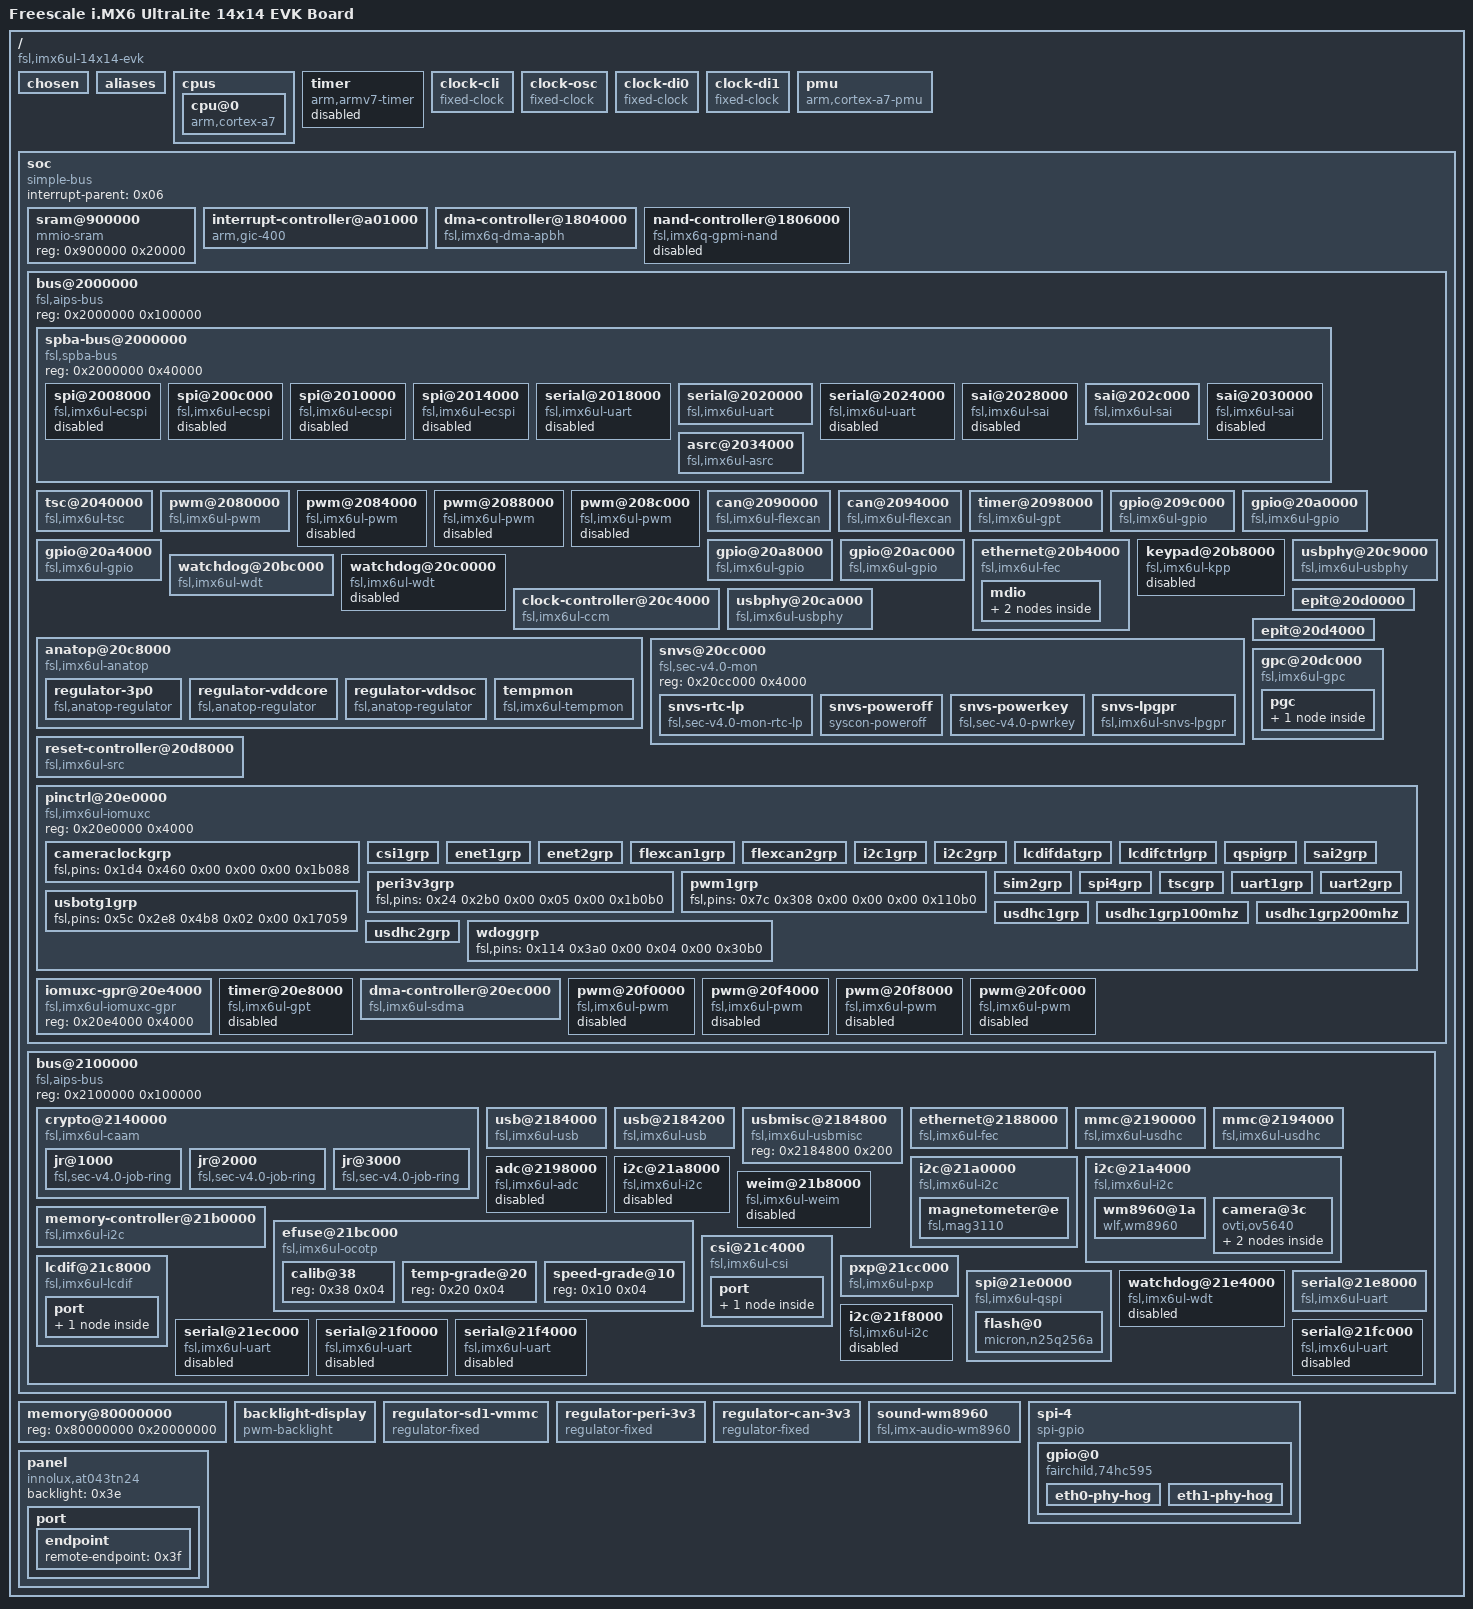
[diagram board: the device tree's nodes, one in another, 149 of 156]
/dts-v1/;

/ {
	#address-cells = <0x01>;
	#size-cells = <0x01>;
	model = "Freescale i.MX6 UltraLite 14x14 EVK Board";
	compatible = "fsl,imx6ul-14x14-evk\0fsl,imx6ul";

	chosen {
		stdout-path = "/soc/bus@2000000/spba-bus@2000000/serial@2020000";
	};

	aliases {
		ethernet0 = "/soc/bus@2100000/ethernet@2188000";
		ethernet1 = "/soc/bus@2000000/ethernet@20b4000";
		gpio0 = "/soc/bus@2000000/gpio@209c000";
		gpio1 = "/soc/bus@2000000/gpio@20a0000";
		gpio2 = "/soc/bus@2000000/gpio@20a4000";
		gpio3 = "/soc/bus@2000000/gpio@20a8000";
		gpio4 = "/soc/bus@2000000/gpio@20ac000";
		i2c0 = "/soc/bus@2100000/i2c@21a0000";
		i2c1 = "/soc/bus@2100000/i2c@21a4000";
		i2c2 = "/soc/bus@2100000/i2c@21a8000";
		i2c3 = "/soc/bus@2100000/i2c@21f8000";
		mmc0 = "/soc/bus@2100000/mmc@2190000";
		mmc1 = "/soc/bus@2100000/mmc@2194000";
		serial0 = "/soc/bus@2000000/spba-bus@2000000/serial@2020000";
		serial1 = "/soc/bus@2100000/serial@21e8000";
		serial2 = "/soc/bus@2100000/serial@21ec000";
		serial3 = "/soc/bus@2100000/serial@21f0000";
		serial4 = "/soc/bus@2100000/serial@21f4000";
		serial5 = "/soc/bus@2100000/serial@21fc000";
		serial6 = "/soc/bus@2000000/spba-bus@2000000/serial@2018000";
		serial7 = "/soc/bus@2000000/spba-bus@2000000/serial@2024000";
		sai1 = "/soc/bus@2000000/spba-bus@2000000/sai@2028000";
		sai2 = "/soc/bus@2000000/spba-bus@2000000/sai@202c000";
		sai3 = "/soc/bus@2000000/spba-bus@2000000/sai@2030000";
		spi0 = "/soc/bus@2000000/spba-bus@2000000/spi@2008000";
		spi1 = "/soc/bus@2000000/spba-bus@2000000/spi@200c000";
		spi2 = "/soc/bus@2000000/spba-bus@2000000/spi@2010000";
		spi3 = "/soc/bus@2000000/spba-bus@2000000/spi@2014000";
		usb0 = "/soc/bus@2100000/usb@2184000";
		usb1 = "/soc/bus@2100000/usb@2184200";
		usbphy0 = "/soc/bus@2000000/usbphy@20c9000";
		usbphy1 = "/soc/bus@2000000/usbphy@20ca000";
	};

	cpus {
		#address-cells = <0x01>;
		#size-cells = <0x00>;

		cpu@0 {
			compatible = "arm,cortex-a7";
			device_type = "cpu";
			reg = <0x00>;
			clock-frequency = <0x297c1e00>;
			clock-latency = <0xee6c>;
			#cooling-cells = <0x02>;
			operating-points = <0xa9ec0 0x137478 0x80e80 0x11edd8 0x60ae0 0xfa3e8 0x30570 0xe7ef0>;
			fsl,soc-operating-points = <0xa9ec0 0x137478 0x80e80 0x11edd8 0x60ae0 0x11edd8 0x30570 0x11edd8>;
			clocks = <0x01 0x5d 0x01 0x1a 0x01 0x26 0x01 0xdb 0x01 0x38 0x01 0x39 0x01 0x19>;
			clock-names = "arm\0pll2_bus\0pll2_pfd2_396m\0secondary_sel\0step\0pll1_sw\0pll1_sys";
			arm-supply = <0x02>;
			soc-supply = <0x03>;
			nvmem-cells = <0x04>;
			nvmem-cell-names = "speed_grade";
		};
	};

	timer {
		compatible = "arm,armv7-timer";
		interrupts = <0x01 0x0d 0x108 0x01 0x0e 0x108 0x01 0x0b 0x108 0x01 0x0a 0x108>;
		interrupt-parent = <0x05>;
		status = "disabled";
	};

	clock-cli {
		compatible = "fixed-clock";
		#clock-cells = <0x00>;
		clock-frequency = <0x8000>;
		clock-output-names = "ckil";
		phandle = <0x17>;
	};

	clock-osc {
		compatible = "fixed-clock";
		#clock-cells = <0x00>;
		clock-frequency = <0x16e3600>;
		clock-output-names = "osc";
		phandle = <0x18>;
	};

	clock-di0 {
		compatible = "fixed-clock";
		#clock-cells = <0x00>;
		clock-frequency = <0x00>;
		clock-output-names = "ipp_di0";
		phandle = <0x19>;
	};

	clock-di1 {
		compatible = "fixed-clock";
		#clock-cells = <0x00>;
		clock-frequency = <0x00>;
		clock-output-names = "ipp_di1";
		phandle = <0x1a>;
	};

	pmu {
		compatible = "arm,cortex-a7-pmu";
		interrupt-parent = <0x06>;
		interrupts = <0x00 0x5e 0x04>;
	};

	soc {
		#address-cells = <0x01>;
		#size-cells = <0x01>;
		compatible = "simple-bus";
		interrupt-parent = <0x06>;
		ranges;

		sram@900000 {
			compatible = "mmio-sram";
			reg = <0x900000 0x20000>;
			ranges = <0x00 0x900000 0x20000>;
			#address-cells = <0x01>;
			#size-cells = <0x01>;
		};

		interrupt-controller@a01000 {
			compatible = "arm,gic-400\0arm,cortex-a7-gic";
			interrupts = <0x01 0x09 0x104>;
			#interrupt-cells = <0x03>;
			interrupt-controller;
			interrupt-parent = <0x05>;
			reg = <0xa01000 0x1000 0xa02000 0x2000 0xa04000 0x2000 0xa06000 0x2000>;
			phandle = <0x05>;
		};

		dma-controller@1804000 {
			compatible = "fsl,imx6q-dma-apbh\0fsl,imx28-dma-apbh";
			reg = <0x1804000 0x2000>;
			interrupts = <0x00 0x0d 0x04 0x00 0x0d 0x04 0x00 0x0d 0x04 0x00 0x0d 0x04>;
			#dma-cells = <0x01>;
			dma-channels = <0x04>;
			clocks = <0x01 0x80>;
			phandle = <0x07>;
		};

		nand-controller@1806000 {
			compatible = "fsl,imx6q-gpmi-nand";
			#address-cells = <0x01>;
			#size-cells = <0x00>;
			reg = <0x1806000 0x2000 0x1808000 0x2000>;
			reg-names = "gpmi-nand\0bch";
			interrupts = <0x00 0x0f 0x04>;
			interrupt-names = "bch";
			clocks = <0x01 0x85 0x01 0x86 0x01 0x84 0x01 0x83 0x01 0xdc>;
			clock-names = "gpmi_io\0gpmi_apb\0gpmi_bch\0gpmi_bch_apb\0per1_bch";
			dmas = <0x07 0x00>;
			dma-names = "rx-tx";
			status = "disabled";
		};

		bus@2000000 {
			compatible = "fsl,aips-bus\0simple-bus";
			#address-cells = <0x01>;
			#size-cells = <0x01>;
			reg = <0x2000000 0x100000>;
			ranges;

			spba-bus@2000000 {
				compatible = "fsl,spba-bus\0simple-bus";
				#address-cells = <0x01>;
				#size-cells = <0x01>;
				reg = <0x2000000 0x40000>;
				ranges;

				spi@2008000 {
					#address-cells = <0x01>;
					#size-cells = <0x00>;
					compatible = "fsl,imx6ul-ecspi\0fsl,imx51-ecspi";
					reg = <0x2008000 0x4000>;
					interrupts = <0x00 0x1f 0x04>;
					clocks = <0x01 0x8b 0x01 0x8b>;
					clock-names = "ipg\0per";
					dmas = <0x08 0x03 0x07 0x01 0x08 0x04 0x07 0x02>;
					dma-names = "rx\0tx";
					status = "disabled";
				};

				spi@200c000 {
					#address-cells = <0x01>;
					#size-cells = <0x00>;
					compatible = "fsl,imx6ul-ecspi\0fsl,imx51-ecspi";
					reg = <0x200c000 0x4000>;
					interrupts = <0x00 0x20 0x04>;
					clocks = <0x01 0x8c 0x01 0x8c>;
					clock-names = "ipg\0per";
					dmas = <0x08 0x05 0x07 0x01 0x08 0x06 0x07 0x02>;
					dma-names = "rx\0tx";
					status = "disabled";
				};

				spi@2010000 {
					#address-cells = <0x01>;
					#size-cells = <0x00>;
					compatible = "fsl,imx6ul-ecspi\0fsl,imx51-ecspi";
					reg = <0x2010000 0x4000>;
					interrupts = <0x00 0x21 0x04>;
					clocks = <0x01 0x8d 0x01 0x8d>;
					clock-names = "ipg\0per";
					dmas = <0x08 0x07 0x07 0x01 0x08 0x08 0x07 0x02>;
					dma-names = "rx\0tx";
					status = "disabled";
				};

				spi@2014000 {
					#address-cells = <0x01>;
					#size-cells = <0x00>;
					compatible = "fsl,imx6ul-ecspi\0fsl,imx51-ecspi";
					reg = <0x2014000 0x4000>;
					interrupts = <0x00 0x22 0x04>;
					clocks = <0x01 0x8e 0x01 0x8e>;
					clock-names = "ipg\0per";
					dmas = <0x08 0x09 0x07 0x01 0x08 0x0a 0x07 0x02>;
					dma-names = "rx\0tx";
					status = "disabled";
				};

				serial@2018000 {
					compatible = "fsl,imx6ul-uart\0fsl,imx6q-uart";
					reg = <0x2018000 0x4000>;
					interrupts = <0x00 0x27 0x04>;
					clocks = <0x01 0xc9 0x01 0xca>;
					clock-names = "ipg\0per";
					status = "disabled";
				};

				serial@2020000 {
					compatible = "fsl,imx6ul-uart\0fsl,imx6q-uart";
					reg = <0x2020000 0x4000>;
					interrupts = <0x00 0x1a 0x04>;
					clocks = <0x01 0xbd 0x01 0xbe>;
					clock-names = "ipg\0per";
					status = "okay";
					pinctrl-names = "default";
					pinctrl-0 = <0x09>;
				};

				serial@2024000 {
					compatible = "fsl,imx6ul-uart\0fsl,imx6q-uart";
					reg = <0x2024000 0x4000>;
					interrupts = <0x00 0x28 0x04>;
					clocks = <0x01 0xcb 0x01 0xcc>;
					clock-names = "ipg\0per";
					status = "disabled";
				};

				sai@2028000 {
					#sound-dai-cells = <0x00>;
					compatible = "fsl,imx6ul-sai\0fsl,imx6sx-sai";
					reg = <0x2028000 0x4000>;
					interrupts = <0x00 0x61 0x04>;
					clocks = <0x01 0xb3 0x01 0xb2 0x01 0x00 0x01 0x00>;
					clock-names = "bus\0mclk1\0mclk2\0mclk3";
					dmas = <0x08 0x23 0x18 0x00 0x08 0x24 0x18 0x00>;
					dma-names = "rx\0tx";
					status = "disabled";
				};

				sai@202c000 {
					#sound-dai-cells = <0x00>;
					compatible = "fsl,imx6ul-sai\0fsl,imx6sx-sai";
					reg = <0x202c000 0x4000>;
					interrupts = <0x00 0x62 0x04>;
					clocks = <0x01 0xb5 0x01 0xb4 0x01 0x00 0x01 0x00>;
					clock-names = "bus\0mclk1\0mclk2\0mclk3";
					dmas = <0x08 0x25 0x18 0x00 0x08 0x26 0x18 0x00>;
					dma-names = "rx\0tx";
					status = "okay";
					pinctrl-names = "default";
					pinctrl-0 = <0x0a>;
					assigned-clocks = <0x01 0x47 0x01 0xb4>;
					assigned-clock-parents = <0x01 0x32>;
					assigned-clock-rates = <0x00 0xbb8000>;
					fsl,sai-mclk-direction-output;
					phandle = <0x3a>;
				};

				sai@2030000 {
					#sound-dai-cells = <0x00>;
					compatible = "fsl,imx6ul-sai\0fsl,imx6sx-sai";
					reg = <0x2030000 0x4000>;
					interrupts = <0x00 0x18 0x04>;
					clocks = <0x01 0xb7 0x01 0xb6 0x01 0x00 0x01 0x00>;
					clock-names = "bus\0mclk1\0mclk2\0mclk3";
					dmas = <0x08 0x27 0x18 0x00 0x08 0x28 0x18 0x00>;
					dma-names = "rx\0tx";
					status = "disabled";
				};

				asrc@2034000 {
					compatible = "fsl,imx6ul-asrc\0fsl,imx53-asrc";
					reg = <0x2034000 0x4000>;
					interrupts = <0x00 0x32 0x04>;
					clocks = <0x01 0x81 0x01 0x82 0x01 0x00 0x01 0x00 0x01 0x00 0x01 0x00 0x01 0x00 0x01 0x00 0x01 0x00 0x01 0x00 0x01 0x00 0x01 0x00 0x01 0x00 0x01 0x00 0x01 0x00 0x01 0xbc 0x01 0x00 0x01 0x00 0x01 0xbb>;
					clock-names = "mem\0ipg\0asrck_0\0asrck_1\0asrck_2\0asrck_3\0asrck_4\0asrck_5\0asrck_6\0asrck_7\0asrck_8\0asrck_9\0asrck_a\0asrck_b\0asrck_c\0asrck_d\0asrck_e\0asrck_f\0spba";
					dmas = <0x08 0x11 0x17 0x01 0x08 0x12 0x17 0x01 0x08 0x13 0x17 0x01 0x08 0x14 0x17 0x01 0x08 0x15 0x17 0x01 0x08 0x16 0x17 0x01>;
					dma-names = "rxa\0rxb\0rxc\0txa\0txb\0txc";
					fsl,asrc-rate = <0xbb80>;
					fsl,asrc-width = <0x10>;
					status = "okay";
					phandle = <0x3c>;
				};
			};

			tsc@2040000 {
				compatible = "fsl,imx6ul-tsc";
				reg = <0x2040000 0x4000 0x219c000 0x4000>;
				interrupts = <0x00 0x03 0x04 0x00 0x65 0x04>;
				clocks = <0x01 0x64 0x01 0x7c>;
				clock-names = "tsc\0adc";
				status = "okay";
				pinctrl-names = "default";
				pinctrl-0 = <0x0b>;
				xnur-gpio = <0x0c 0x03 0x01>;
				measure-delay-time = <0xffff>;
				pre-charge-time = <0xfff>;
			};

			pwm@2080000 {
				compatible = "fsl,imx6ul-pwm\0fsl,imx27-pwm";
				reg = <0x2080000 0x4000>;
				interrupts = <0x00 0x53 0x04>;
				clocks = <0x01 0xa7 0x01 0xa7>;
				clock-names = "ipg\0per";
				#pwm-cells = <0x02>;
				status = "okay";
				pinctrl-names = "default";
				pinctrl-0 = <0x0d>;
				phandle = <0x37>;
			};

			pwm@2084000 {
				compatible = "fsl,imx6ul-pwm\0fsl,imx27-pwm";
				reg = <0x2084000 0x4000>;
				interrupts = <0x00 0x54 0x04>;
				clocks = <0x01 0xa8 0x01 0xa8>;
				clock-names = "ipg\0per";
				#pwm-cells = <0x03>;
				status = "disabled";
			};

			pwm@2088000 {
				compatible = "fsl,imx6ul-pwm\0fsl,imx27-pwm";
				reg = <0x2088000 0x4000>;
				interrupts = <0x00 0x55 0x04>;
				clocks = <0x01 0xa9 0x01 0xa9>;
				clock-names = "ipg\0per";
				#pwm-cells = <0x03>;
				status = "disabled";
			};

			pwm@208c000 {
				compatible = "fsl,imx6ul-pwm\0fsl,imx27-pwm";
				reg = <0x208c000 0x4000>;
				interrupts = <0x00 0x56 0x04>;
				clocks = <0x01 0xaa 0x01 0xaa>;
				clock-names = "ipg\0per";
				#pwm-cells = <0x03>;
				status = "disabled";
			};

			can@2090000 {
				compatible = "fsl,imx6ul-flexcan\0fsl,imx6q-flexcan";
				reg = <0x2090000 0x4000>;
				interrupts = <0x00 0x6e 0x04>;
				clocks = <0x01 0x94 0x01 0x95>;
				clock-names = "ipg\0per";
				fsl,stop-mode = <0x0e 0x10 0x01>;
				status = "okay";
				pinctrl-names = "default";
				pinctrl-0 = <0x0f>;
				xceiver-supply = <0x10>;
			};

			can@2094000 {
				compatible = "fsl,imx6ul-flexcan\0fsl,imx6q-flexcan";
				reg = <0x2094000 0x4000>;
				interrupts = <0x00 0x6f 0x04>;
				clocks = <0x01 0x96 0x01 0x97>;
				clock-names = "ipg\0per";
				fsl,stop-mode = <0x0e 0x10 0x02>;
				status = "okay";
				pinctrl-names = "default";
				pinctrl-0 = <0x11>;
				xceiver-supply = <0x10>;
			};

			timer@2098000 {
				compatible = "fsl,imx6ul-gpt\0fsl,imx6sx-gpt";
				reg = <0x2098000 0x4000>;
				interrupts = <0x00 0x37 0x04>;
				clocks = <0x01 0x98 0x01 0x99>;
				clock-names = "ipg\0per";
			};

			gpio@209c000 {
				compatible = "fsl,imx6ul-gpio\0fsl,imx35-gpio";
				reg = <0x209c000 0x4000>;
				interrupts = <0x00 0x42 0x04 0x00 0x43 0x04>;
				clocks = <0x01 0xf4>;
				gpio-controller;
				#gpio-cells = <0x02>;
				interrupt-controller;
				#interrupt-cells = <0x02>;
				gpio-ranges = <0x12 0x00 0x17 0x0a 0x12 0x0a 0x11 0x06 0x12 0x10 0x21 0x10>;
				phandle = <0x0c>;
			};

			gpio@20a0000 {
				compatible = "fsl,imx6ul-gpio\0fsl,imx35-gpio";
				reg = <0x20a0000 0x4000>;
				interrupts = <0x00 0x44 0x04 0x00 0x45 0x04>;
				clocks = <0x01 0xf5>;
				gpio-controller;
				#gpio-cells = <0x02>;
				interrupt-controller;
				#interrupt-cells = <0x02>;
				gpio-ranges = <0x12 0x00 0x31 0x10 0x12 0x10 0x6f 0x06>;
			};

			gpio@20a4000 {
				compatible = "fsl,imx6ul-gpio\0fsl,imx35-gpio";
				reg = <0x20a4000 0x4000>;
				interrupts = <0x00 0x46 0x04 0x00 0x47 0x04>;
				clocks = <0x01 0xf6>;
				gpio-controller;
				#gpio-cells = <0x02>;
				interrupt-controller;
				#interrupt-cells = <0x02>;
				gpio-ranges = <0x12 0x00 0x41 0x1d>;
			};

			gpio@20a8000 {
				compatible = "fsl,imx6ul-gpio\0fsl,imx35-gpio";
				reg = <0x20a8000 0x4000>;
				interrupts = <0x00 0x48 0x04 0x00 0x49 0x04>;
				clocks = <0x01 0xf7>;
				gpio-controller;
				#gpio-cells = <0x02>;
				interrupt-controller;
				#interrupt-cells = <0x02>;
				gpio-ranges = <0x12 0x00 0x5e 0x11 0x12 0x11 0x75 0x0c>;
			};

			gpio@20ac000 {
				compatible = "fsl,imx6ul-gpio\0fsl,imx35-gpio";
				reg = <0x20ac000 0x4000>;
				interrupts = <0x00 0x4a 0x04 0x00 0x4b 0x04>;
				clocks = <0x01 0xf8>;
				gpio-controller;
				#gpio-cells = <0x02>;
				interrupt-controller;
				#interrupt-cells = <0x02>;
				gpio-ranges = <0x12 0x00 0x07 0x0a 0x12 0x0a 0x05 0x02>;
				phandle = <0x39>;
			};

			ethernet@20b4000 {
				compatible = "fsl,imx6ul-fec\0fsl,imx6q-fec";
				reg = <0x20b4000 0x4000>;
				interrupt-names = "int0\0pps";
				interrupts = <0x00 0x78 0x04 0x00 0x79 0x04>;
				clocks = <0x01 0x90 0x01 0x91 0x01 0x30 0x01 0xfd>;
				clock-names = "ipg\0ahb\0ptp\0enet_clk_ref";
				fsl,num-tx-queues = <0x01>;
				fsl,num-rx-queues = <0x01>;
				fsl,stop-mode = <0x0e 0x10 0x04>;
				fsl,magic-packet;
				status = "okay";
				pinctrl-names = "default";
				pinctrl-0 = <0x13>;
				phy-mode = "rmii";
				phy-handle = <0x14>;
				phy-supply = <0x15>;

				mdio {
					#address-cells = <0x01>;
					#size-cells = <0x00>;

					ethernet-phy@2 {
						compatible = "ethernet-phy-id0022.1560";
						reg = <0x02>;
						micrel,led-mode = <0x01>;
						clocks = <0x01 0x2c>;
						clock-names = "rmii-ref";
						phandle = <0x25>;
					};

					ethernet-phy@1 {
						compatible = "ethernet-phy-id0022.1560";
						reg = <0x01>;
						micrel,led-mode = <0x01>;
						clocks = <0x01 0x2d>;
						clock-names = "rmii-ref";
						phandle = <0x14>;
					};
				};
			};

			keypad@20b8000 {
				compatible = "fsl,imx6ul-kpp\0fsl,imx21-kpp";
				reg = <0x20b8000 0x4000>;
				interrupts = <0x00 0x52 0x04>;
				clocks = <0x01 0xe0>;
				status = "disabled";
			};

			watchdog@20bc000 {
				compatible = "fsl,imx6ul-wdt\0fsl,imx21-wdt";
				reg = <0x20bc000 0x4000>;
				interrupts = <0x00 0x50 0x04>;
				clocks = <0x01 0xd0>;
				pinctrl-names = "default";
				pinctrl-0 = <0x16>;
				fsl,ext-reset-output;
			};

			watchdog@20c0000 {
				compatible = "fsl,imx6ul-wdt\0fsl,imx21-wdt";
				reg = <0x20c0000 0x4000>;
				interrupts = <0x00 0x51 0x04>;
				clocks = <0x01 0xd1>;
				status = "disabled";
			};

			clock-controller@20c4000 {
				compatible = "fsl,imx6ul-ccm";
				reg = <0x20c4000 0x4000>;
				interrupts = <0x00 0x57 0x04 0x00 0x58 0x04>;
				#clock-cells = <0x01>;
				clocks = <0x17 0x18 0x19 0x1a>;
				clock-names = "ckil\0osc\0ipp_di0\0ipp_di1";
				assigned-clocks = <0x01 0x32>;
				assigned-clock-rates = <0x2ee00000>;
				phandle = <0x01>;
			};

			anatop@20c8000 {
				compatible = "fsl,imx6ul-anatop\0fsl,imx6q-anatop\0syscon\0simple-mfd";
				reg = <0x20c8000 0x1000>;
				interrupts = <0x00 0x31 0x04 0x00 0x36 0x04 0x00 0x7f 0x04>;
				phandle = <0x1b>;

				regulator-3p0 {
					compatible = "fsl,anatop-regulator";
					regulator-name = "vdd3p0";
					regulator-min-microvolt = <0x280de8>;
					regulator-max-microvolt = <0x33e140>;
					anatop-reg-offset = <0x120>;
					anatop-vol-bit-shift = <0x08>;
					anatop-vol-bit-width = <0x05>;
					anatop-min-bit-val = <0x00>;
					anatop-min-voltage = <0x280de8>;
					anatop-max-voltage = <0x33e140>;
					anatop-enable-bit = <0x00>;
					phandle = <0x1e>;
				};

				regulator-vddcore {
					compatible = "fsl,anatop-regulator";
					regulator-name = "cpu";
					regulator-min-microvolt = <0xb1008>;
					regulator-max-microvolt = <0x162010>;
					regulator-always-on;
					anatop-reg-offset = <0x140>;
					anatop-vol-bit-shift = <0x00>;
					anatop-vol-bit-width = <0x05>;
					anatop-delay-reg-offset = <0x170>;
					anatop-delay-bit-shift = <0x18>;
					anatop-delay-bit-width = <0x02>;
					anatop-min-bit-val = <0x01>;
					anatop-min-voltage = <0xb1008>;
					anatop-max-voltage = <0x162010>;
					phandle = <0x02>;
				};

				regulator-vddsoc {
					compatible = "fsl,anatop-regulator";
					regulator-name = "vddsoc";
					regulator-min-microvolt = <0xb1008>;
					regulator-max-microvolt = <0x162010>;
					regulator-always-on;
					anatop-reg-offset = <0x140>;
					anatop-vol-bit-shift = <0x12>;
					anatop-vol-bit-width = <0x05>;
					anatop-delay-reg-offset = <0x170>;
					anatop-delay-bit-shift = <0x1c>;
					anatop-delay-bit-width = <0x02>;
					anatop-min-bit-val = <0x01>;
					anatop-min-voltage = <0xb1008>;
					anatop-max-voltage = <0x162010>;
					phandle = <0x03>;
				};

				tempmon {
					compatible = "fsl,imx6ul-tempmon\0fsl,imx6sx-tempmon";
					interrupt-parent = <0x06>;
					interrupts = <0x00 0x31 0x04>;
					fsl,tempmon = <0x1b>;
					nvmem-cells = <0x1c 0x1d>;
					nvmem-cell-names = "calib\0temp_grade";
					clocks = <0x01 0x1b>;
				};
			};

			usbphy@20c9000 {
				compatible = "fsl,imx6ul-usbphy\0fsl,imx23-usbphy";
				reg = <0x20c9000 0x1000>;
				interrupts = <0x00 0x2c 0x04>;
				clocks = <0x01 0x20>;
				phy-3p0-supply = <0x1e>;
				fsl,anatop = <0x1b>;
				fsl,tx-d-cal = <0x6a>;
				phandle = <0x20>;
			};

			usbphy@20ca000 {
				compatible = "fsl,imx6ul-usbphy\0fsl,imx23-usbphy";
				reg = <0x20ca000 0x1000>;
				interrupts = <0x00 0x2d 0x04>;
				clocks = <0x01 0x21>;
				phy-3p0-supply = <0x1e>;
				fsl,anatop = <0x1b>;
				fsl,tx-d-cal = <0x6a>;
				phandle = <0x23>;
			};

			snvs@20cc000 {
				compatible = "fsl,sec-v4.0-mon\0syscon\0simple-mfd";
				reg = <0x20cc000 0x4000>;
				phandle = <0x1f>;

				snvs-rtc-lp {
					compatible = "fsl,sec-v4.0-mon-rtc-lp";
					regmap = <0x1f>;
					offset = <0x34>;
					interrupts = <0x00 0x13 0x04 0x00 0x14 0x04>;
				};

				snvs-poweroff {
					compatible = "syscon-poweroff";
					regmap = <0x1f>;
					offset = <0x38>;
					value = <0x60>;
					mask = <0x60>;
					status = "okay";
				};

				snvs-powerkey {
					compatible = "fsl,sec-v4.0-pwrkey";
					regmap = <0x1f>;
					interrupts = <0x00 0x04 0x04>;
					linux,keycode = <0x74>;
					wakeup-source;
					status = "okay";
				};

				snvs-lpgpr {
					compatible = "fsl,imx6ul-snvs-lpgpr";
				};
			};

			epit@20d0000 {
				reg = <0x20d0000 0x4000>;
				interrupts = <0x00 0x38 0x04>;
			};

			epit@20d4000 {
				reg = <0x20d4000 0x4000>;
				interrupts = <0x00 0x39 0x04>;
			};

			reset-controller@20d8000 {
				compatible = "fsl,imx6ul-src\0fsl,imx51-src";
				reg = <0x20d8000 0x4000>;
				interrupts = <0x00 0x5b 0x04 0x00 0x60 0x04>;
				#reset-cells = <0x01>;
			};

			gpc@20dc000 {
				compatible = "fsl,imx6ul-gpc\0fsl,imx6q-gpc";
				reg = <0x20dc000 0x4000>;
				interrupt-controller;
				#interrupt-cells = <0x03>;
				interrupts = <0x00 0x59 0x04>;
				interrupt-parent = <0x05>;
				clocks = <0x01 0x64>;
				clock-names = "ipg";
				phandle = <0x06>;

				pgc {
					#address-cells = <0x01>;
					#size-cells = <0x00>;

					power-domain@0 {
						reg = <0x00>;
						#power-domain-cells = <0x00>;
					};
				};
			};

			pinctrl@20e0000 {
				compatible = "fsl,imx6ul-iomuxc";
				reg = <0x20e0000 0x4000>;
				pinctrl-names = "default";
				phandle = <0x12>;

				cameraclockgrp {
					fsl,pins = <0x1d4 0x460 0x00 0x00 0x00 0x1b088>;
					phandle = <0x2d>;
				};

				csi1grp {
					fsl,pins = <0x1d8 0x464 0x528 0x00 0x01 0x1b088 0x1dc 0x468 0x52c 0x00 0x00 0x1b088 0x1e0 0x46c 0x524 0x00 0x00 0x1b088 0x1e4 0x470 0x4c4 0x00 0x00 0x1b088 0x1e8 0x474 0x4c8 0x00 0x00 0x1b088 0x1ec 0x478 0x4d8 0x00 0x01 0x1b088 0x1f0 0x47c 0x4cc 0x00 0x00 0x1b088 0x1f4 0x480 0x4dc 0x00 0x01 0x1b088 0x1f8 0x484 0x4e0 0x00 0x01 0x1b088 0x1fc 0x488 0x4e4 0x00 0x01 0x1b088 0x200 0x48c 0x4e8 0x00 0x01 0x1b088>;
					phandle = <0x30>;
				};

				enet1grp {
					fsl,pins = <0xcc 0x358 0x00 0x00 0x00 0x1b0b0 0xe0 0x36c 0x00 0x00 0x00 0x1b0b0 0xc4 0x350 0x00 0x00 0x00 0x1b0b0 0xc8 0x354 0x00 0x00 0x00 0x1b0b0 0xd8 0x364 0x00 0x00 0x00 0x1b0b0 0xd0 0x35c 0x00 0x00 0x00 0x1b0b0 0xd4 0x360 0x00 0x00 0x00 0x1b0b0 0xdc 0x368 0x574 0x04 0x02 0x4001b031>;
					phandle = <0x24>;
				};

				enet2grp {
					fsl,pins = <0x78 0x304 0x00 0x01 0x00 0x1b0b0 0x74 0x300 0x580 0x01 0x00 0x1b0b0 0xec 0x378 0x00 0x00 0x00 0x1b0b0 0x100 0x38c 0x00 0x00 0x00 0x1b0b0 0xe4 0x370 0x00 0x00 0x00 0x1b0b0 0xe8 0x374 0x00 0x00 0x00 0x1b0b0 0xf8 0x384 0x00 0x00 0x00 0x1b0b0 0xf0 0x37c 0x00 0x00 0x00 0x1b0b0 0xf4 0x380 0x00 0x00 0x00 0x1b0b0 0xfc 0x388 0x57c 0x04 0x02 0x4001b031>;
					phandle = <0x13>;
				};

				flexcan1grp {
					fsl,pins = <0xb0 0x33c 0x584 0x02 0x00 0x1b020 0xac 0x338 0x00 0x02 0x00 0x1b020>;
					phandle = <0x0f>;
				};

				flexcan2grp {
					fsl,pins = <0xa0 0x32c 0x588 0x02 0x00 0x1b020 0x9c 0x328 0x00 0x02 0x00 0x1b020>;
					phandle = <0x11>;
				};

				i2c1grp {
					fsl,pins = <0xb4 0x340 0x5a4 0x02 0x01 0x4001b8b0 0xb8 0x344 0x5a8 0x02 0x02 0x4001b8b0>;
					phandle = <0x2b>;
				};

				i2c2grp {
					fsl,pins = <0xbc 0x348 0x5ac 0x02 0x02 0x4001b8b0 0xc0 0x34c 0x5b0 0x02 0x02 0x4001b8b0>;
					phandle = <0x2c>;
				};

				lcdifdatgrp {
					fsl,pins = <0x118 0x3a4 0x00 0x00 0x00 0x79 0x11c 0x3a8 0x00 0x00 0x00 0x79 0x120 0x3ac 0x00 0x00 0x00 0x79 0x124 0x3b0 0x00 0x00 0x00 0x79 0x128 0x3b4 0x00 0x00 0x00 0x79 0x12c 0x3b8 0x00 0x00 0x00 0x79 0x130 0x3bc 0x00 0x00 0x00 0x79 0x134 0x3c0 0x00 0x00 0x00 0x79 0x138 0x3c4 0x00 0x00 0x00 0x79 0x13c 0x3c8 0x00 0x00 0x00 0x79 0x140 0x3cc 0x00 0x00 0x00 0x79 0x144 0x3d0 0x00 0x00 0x00 0x79 0x148 0x3d4 0x00 0x00 0x00 0x79 0x14c 0x3d8 0x00 0x00 0x00 0x79 0x150 0x3dc 0x00 0x00 0x00 0x79 0x154 0x3e0 0x00 0x00 0x00 0x79 0x158 0x3e4 0x00 0x00 0x00 0x79 0x15c 0x3e8 0x00 0x00 0x00 0x79 0x160 0x3ec 0x00 0x00 0x00 0x79 0x164 0x3f0 0x00 0x00 0x00 0x79 0x168 0x3f4 0x00 0x00 0x00 0x79 0x16c 0x3f8 0x00 0x00 0x00 0x79 0x170 0x3fc 0x00 0x00 0x00 0x79 0x174 0x400 0x00 0x00 0x00 0x79>;
					phandle = <0x32>;
				};

				lcdifctrlgrp {
					fsl,pins = <0x104 0x390 0x00 0x00 0x00 0x79 0x108 0x394 0x00 0x00 0x00 0x79 0x10c 0x398 0x5dc 0x00 0x00 0x79 0x110 0x39c 0x00 0x00 0x00 0x79 0x40 0x2cc 0x00 0x05 0x00 0x79>;
					phandle = <0x33>;
				};

				qspigrp {
					fsl,pins = <0x1a4 0x430 0x00 0x02 0x00 0x70a1 0x1a8 0x434 0x00 0x02 0x00 0x70a1 0x1ac 0x438 0x00 0x02 0x00 0x70a1 0x1b0 0x43c 0x00 0x02 0x00 0x70a1 0x1b4 0x440 0x00 0x02 0x00 0x70a1 0x1b8 0x444 0x00 0x02 0x00 0x70a1>;
					phandle = <0x35>;
				};

				sai2grp {
					fsl,pins = <0x50 0x2dc 0x5f8 0x02 0x00 0x17088 0x4c 0x2d8 0x5fc 0x02 0x00 0x17088 0x58 0x2e4 0x00 0x02 0x00 0x11088 0x54 0x2e0 0x5f4 0x02 0x00 0x11088 0x48 0x2d4 0x5f0 0x02 0x00 0x17088 0x2c 0x2b8 0x00 0x05 0x00 0x17059>;
					phandle = <0x0a>;
				};

				peri3v3grp {
					fsl,pins = <0x24 0x2b0 0x00 0x05 0x00 0x1b0b0>;
					phandle = <0x38>;
				};

				pwm1grp {
					fsl,pins = <0x7c 0x308 0x00 0x00 0x00 0x110b0>;
					phandle = <0x0d>;
				};

				sim2grp {
					fsl,pins = <0x1f0 0x47c 0x00 0x02 0x00 0xb808 0x1f4 0x480 0x00 0x02 0x00 0x31 0x1f8 0x484 0x00 0x02 0x00 0xb808 0x1fc 0x488 0x00 0x02 0x00 0xb808 0x200 0x48c 0x00 0x02 0x00 0xb809 0x1ec 0x478 0x00 0x05 0x00 0x3008>;
				};

				spi4grp {
					fsl,pins = <0x14 0x2a0 0x00 0x05 0x00 0x70a1 0x18 0x2a4 0x00 0x05 0x00 0x70a1 0x38 0x2c4 0x00 0x05 0x00 0x70a1 0x3c 0x2c8 0x00 0x05 0x00 0x80000000>;
					phandle = <0x3d>;
				};

				tscgrp {
					fsl,pins = <0x60 0x2ec 0x00 0x05 0x00 0xb0 0x64 0x2f0 0x00 0x05 0x00 0xb0 0x68 0x2f4 0x00 0x05 0x00 0xb0 0x6c 0x2f8 0x00 0x05 0x00 0xb0>;
					phandle = <0x0b>;
				};

				uart1grp {
					fsl,pins = <0x84 0x310 0x00 0x00 0x00 0x1b0b1 0x88 0x314 0x624 0x00 0x03 0x1b0b1>;
					phandle = <0x09>;
				};

				uart2grp {
					fsl,pins = <0x94 0x320 0x00 0x00 0x00 0x1b0b1 0x98 0x324 0x62c 0x00 0x01 0x1b0b1 0xa8 0x334 0x628 0x04 0x03 0x1b0b1 0xa4 0x330 0x00 0x04 0x00 0x1b0b1>;
					phandle = <0x36>;
				};

				usbotg1grp {
					fsl,pins = <0x5c 0x2e8 0x4b8 0x02 0x00 0x17059>;
					phandle = <0x22>;
				};

				usdhc1grp {
					fsl,pins = <0x1bc 0x448 0x00 0x00 0x00 0x17059 0x1c0 0x44c 0x00 0x00 0x00 0x10059 0x1c4 0x450 0x00 0x00 0x00 0x17059 0x1c8 0x454 0x00 0x00 0x00 0x17059 0x1cc 0x458 0x00 0x00 0x00 0x17059 0x1d0 0x45c 0x00 0x00 0x00 0x17059 0x90 0x31c 0x00 0x05 0x00 0x17059 0x70 0x2fc 0x00 0x04 0x00 0x17059 0x80 0x30c 0x00 0x05 0x00 0x17059>;
					phandle = <0x26>;
				};

				usdhc1grp100mhz {
					fsl,pins = <0x1bc 0x448 0x00 0x00 0x00 0x170b9 0x1c0 0x44c 0x00 0x00 0x00 0x100b9 0x1c4 0x450 0x00 0x00 0x00 0x170b9 0x1c8 0x454 0x00 0x00 0x00 0x170b9 0x1cc 0x458 0x00 0x00 0x00 0x170b9 0x1d0 0x45c 0x00 0x00 0x00 0x170b9>;
					phandle = <0x27>;
				};

				usdhc1grp200mhz {
					fsl,pins = <0x1bc 0x448 0x00 0x00 0x00 0x170f9 0x1c0 0x44c 0x00 0x00 0x00 0x100f9 0x1c4 0x450 0x00 0x00 0x00 0x170f9 0x1c8 0x454 0x00 0x00 0x00 0x170f9 0x1cc 0x458 0x00 0x00 0x00 0x170f9 0x1d0 0x45c 0x00 0x00 0x00 0x170f9>;
					phandle = <0x28>;
				};

				usdhc2grp {
					fsl,pins = <0x178 0x404 0x670 0x01 0x02 0x17059 0x17c 0x408 0x678 0x01 0x02 0x17059 0x180 0x40c 0x67c 0x01 0x02 0x17059 0x184 0x410 0x680 0x01 0x02 0x17059 0x188 0x414 0x684 0x01 0x01 0x17059 0x18c 0x418 0x688 0x01 0x02 0x17059>;
					phandle = <0x2a>;
				};

				wdoggrp {
					fsl,pins = <0x114 0x3a0 0x00 0x04 0x00 0x30b0>;
					phandle = <0x16>;
				};
			};

			iomuxc-gpr@20e4000 {
				compatible = "fsl,imx6ul-iomuxc-gpr\0fsl,imx6q-iomuxc-gpr\0syscon";
				reg = <0x20e4000 0x4000>;
				phandle = <0x0e>;
			};

			timer@20e8000 {
				compatible = "fsl,imx6ul-gpt\0fsl,imx6sx-gpt";
				reg = <0x20e8000 0x4000>;
				interrupts = <0x00 0x6d 0x04>;
				clocks = <0x01 0x9a 0x01 0x9b>;
				clock-names = "ipg\0per";
				status = "disabled";
			};

			dma-controller@20ec000 {
				compatible = "fsl,imx6ul-sdma\0fsl,imx6q-sdma\0fsl,imx35-sdma";
				reg = <0x20ec000 0x4000>;
				interrupts = <0x00 0x02 0x04>;
				clocks = <0x01 0x64 0x01 0xb8>;
				clock-names = "ipg\0ahb";
				#dma-cells = <0x03>;
				fsl,sdma-ram-script-name = "imx/sdma/sdma-imx6q.bin";
				phandle = <0x08>;
			};

			pwm@20f0000 {
				compatible = "fsl,imx6ul-pwm\0fsl,imx27-pwm";
				reg = <0x20f0000 0x4000>;
				interrupts = <0x00 0x72 0x04>;
				clocks = <0x01 0xab 0x01 0xab>;
				clock-names = "ipg\0per";
				#pwm-cells = <0x03>;
				status = "disabled";
			};

			pwm@20f4000 {
				compatible = "fsl,imx6ul-pwm\0fsl,imx27-pwm";
				reg = <0x20f4000 0x4000>;
				interrupts = <0x00 0x73 0x04>;
				clocks = <0x01 0xac 0x01 0xac>;
				clock-names = "ipg\0per";
				#pwm-cells = <0x03>;
				status = "disabled";
			};

			pwm@20f8000 {
				compatible = "fsl,imx6ul-pwm\0fsl,imx27-pwm";
				reg = <0x20f8000 0x4000>;
				interrupts = <0x00 0x74 0x04>;
				clocks = <0x01 0xad 0x01 0xad>;
				clock-names = "ipg\0per";
				#pwm-cells = <0x03>;
				status = "disabled";
			};

			pwm@20fc000 {
				compatible = "fsl,imx6ul-pwm\0fsl,imx27-pwm";
				reg = <0x20fc000 0x4000>;
				interrupts = <0x00 0x75 0x04>;
				clocks = <0x01 0xae 0x01 0xae>;
				clock-names = "ipg\0per";
				#pwm-cells = <0x03>;
				status = "disabled";
			};
		};

		bus@2100000 {
			compatible = "fsl,aips-bus\0simple-bus";
			#address-cells = <0x01>;
			#size-cells = <0x01>;
			reg = <0x2100000 0x100000>;
			ranges;

			crypto@2140000 {
				compatible = "fsl,imx6ul-caam\0fsl,sec-v4.0";
				#address-cells = <0x01>;
				#size-cells = <0x01>;
				reg = <0x2140000 0x3c000>;
				ranges = <0x00 0x2140000 0x3c000>;
				interrupts = <0x00 0x30 0x04>;
				clocks = <0x01 0x89 0x01 0x88 0x01 0x87>;
				clock-names = "ipg\0aclk\0mem";

				jr@1000 {
					compatible = "fsl,sec-v4.0-job-ring";
					reg = <0x1000 0x1000>;
					interrupts = <0x00 0x69 0x04>;
				};

				jr@2000 {
					compatible = "fsl,sec-v4.0-job-ring";
					reg = <0x2000 0x1000>;
					interrupts = <0x00 0x6a 0x04>;
				};

				jr@3000 {
					compatible = "fsl,sec-v4.0-job-ring";
					reg = <0x3000 0x1000>;
					interrupts = <0x00 0x2e 0x04>;
				};
			};

			usb@2184000 {
				compatible = "fsl,imx6ul-usb\0fsl,imx27-usb";
				reg = <0x2184000 0x200>;
				interrupts = <0x00 0x2b 0x04>;
				clocks = <0x01 0xcd>;
				fsl,usbphy = <0x20>;
				fsl,usbmisc = <0x21 0x00>;
				fsl,anatop = <0x1b>;
				ahb-burst-config = <0x00>;
				tx-burst-size-dword = <0x10>;
				rx-burst-size-dword = <0x10>;
				status = "okay";
				dr_mode = "otg";
				pinctrl-names = "default";
				pinctrl-0 = <0x22>;
			};

			usb@2184200 {
				compatible = "fsl,imx6ul-usb\0fsl,imx27-usb";
				reg = <0x2184200 0x200>;
				interrupts = <0x00 0x2a 0x04>;
				clocks = <0x01 0xcd>;
				fsl,usbphy = <0x23>;
				fsl,usbmisc = <0x21 0x01>;
				ahb-burst-config = <0x00>;
				tx-burst-size-dword = <0x10>;
				rx-burst-size-dword = <0x10>;
				status = "okay";
				dr_mode = "host";
				disable-over-current;
			};

			usbmisc@2184800 {
				#index-cells = <0x01>;
				compatible = "fsl,imx6ul-usbmisc\0fsl,imx6q-usbmisc";
				reg = <0x2184800 0x200>;
				phandle = <0x21>;
			};

			ethernet@2188000 {
				compatible = "fsl,imx6ul-fec\0fsl,imx6q-fec";
				reg = <0x2188000 0x4000>;
				interrupt-names = "int0\0pps";
				interrupts = <0x00 0x76 0x04 0x00 0x77 0x04>;
				clocks = <0x01 0x90 0x01 0x91 0x01 0x30 0x01 0xfb>;
				clock-names = "ipg\0ahb\0ptp\0enet_clk_ref";
				fsl,num-tx-queues = <0x01>;
				fsl,num-rx-queues = <0x01>;
				fsl,stop-mode = <0x0e 0x10 0x03>;
				fsl,magic-packet;
				status = "okay";
				pinctrl-names = "default";
				pinctrl-0 = <0x24>;
				phy-mode = "rmii";
				phy-handle = <0x25>;
				phy-supply = <0x15>;
			};

			mmc@2190000 {
				compatible = "fsl,imx6ul-usdhc\0fsl,imx6sx-usdhc";
				reg = <0x2190000 0x4000>;
				interrupts = <0x00 0x16 0x04>;
				clocks = <0x01 0xce 0x01 0xce 0x01 0xce>;
				clock-names = "ipg\0ahb\0per";
				fsl,tuning-step = <0x02>;
				fsl,tuning-start-tap = <0x14>;
				bus-width = <0x04>;
				status = "okay";
				pinctrl-names = "default\0state_100mhz\0state_200mhz";
				pinctrl-0 = <0x26>;
				pinctrl-1 = <0x27>;
				pinctrl-2 = <0x28>;
				cd-gpios = <0x0c 0x13 0x01>;
				keep-power-in-suspend;
				wakeup-source;
				vmmc-supply = <0x29>;
			};

			mmc@2194000 {
				compatible = "fsl,imx6ul-usdhc\0fsl,imx6sx-usdhc";
				reg = <0x2194000 0x4000>;
				interrupts = <0x00 0x17 0x04>;
				clocks = <0x01 0xcf 0x01 0xcf 0x01 0xcf>;
				clock-names = "ipg\0ahb\0per";
				bus-width = <0x04>;
				fsl,tuning-step = <0x02>;
				fsl,tuning-start-tap = <0x14>;
				status = "okay";
				pinctrl-names = "default";
				pinctrl-0 = <0x2a>;
				no-1-8-v;
				broken-cd;
				keep-power-in-suspend;
				wakeup-source;
			};

			adc@2198000 {
				compatible = "fsl,imx6ul-adc\0fsl,vf610-adc";
				reg = <0x2198000 0x4000>;
				interrupts = <0x00 0x64 0x04>;
				clocks = <0x01 0x7b>;
				clock-names = "adc";
				fsl,adck-max-frequency = <0x1c9c380 0x2625a00 0x1312d00>;
				status = "disabled";
			};

			i2c@21a0000 {
				#address-cells = <0x01>;
				#size-cells = <0x00>;
				compatible = "fsl,imx6ul-i2c\0fsl,imx21-i2c";
				reg = <0x21a0000 0x4000>;
				interrupts = <0x00 0x24 0x04>;
				clocks = <0x01 0x9c>;
				status = "okay";
				clock-frequency = <0x186a0>;
				pinctrl-names = "default";
				pinctrl-0 = <0x2b>;

				magnetometer@e {
					compatible = "fsl,mag3110";
					reg = <0x0e>;
					vdd-supply = <0x15>;
					vddio-supply = <0x15>;
				};
			};

			i2c@21a4000 {
				#address-cells = <0x01>;
				#size-cells = <0x00>;
				compatible = "fsl,imx6ul-i2c\0fsl,imx21-i2c";
				reg = <0x21a4000 0x4000>;
				interrupts = <0x00 0x25 0x04>;
				clocks = <0x01 0x9d>;
				status = "okay";
				clock-frequency = <0x186a0>;
				pinctrl-names = "default";
				pinctrl-0 = <0x2c>;

				wm8960@1a {
					#sound-dai-cells = <0x00>;
					compatible = "wlf,wm8960";
					reg = <0x1a>;
					wlf,shared-lrclk;
					wlf,hp-cfg = <0x03 0x02 0x03>;
					wlf,gpio-cfg = <0x01 0x03>;
					clocks = <0x01 0xb4>;
					clock-names = "mclk";
					phandle = <0x3b>;
				};

				camera@3c {
					compatible = "ovti,ov5640";
					reg = <0x3c>;
					pinctrl-names = "default";
					pinctrl-0 = <0x2d>;
					clocks = <0x01 0x8a>;
					clock-names = "xclk";
					powerdown-gpios = <0x2e 0x06 0x00>;
					reset-gpios = <0x2e 0x05 0x01>;

					port {

						endpoint {
							remote-endpoint = <0x2f>;
							bus-width = <0x08>;
							data-shift = <0x02>;
							hsync-active = <0x00>;
							vsync-active = <0x00>;
							pclk-sample = <0x01>;
							phandle = <0x31>;
						};
					};
				};
			};

			i2c@21a8000 {
				#address-cells = <0x01>;
				#size-cells = <0x00>;
				compatible = "fsl,imx6ul-i2c\0fsl,imx21-i2c";
				reg = <0x21a8000 0x4000>;
				interrupts = <0x00 0x26 0x04>;
				clocks = <0x01 0x9e>;
				status = "disabled";
			};

			memory-controller@21b0000 {
				compatible = "fsl,imx6ul-i2c\0fsl,imx6q-mmdc";
				reg = <0x21b0000 0x4000>;
				clocks = <0x01 0xa4>;				
			};

			weim@21b8000 {
				#address-cells = <0x02>;
				#size-cells = <0x01>;
				compatible = "fsl,imx6ul-weim\0fsl,imx6q-weim";
				reg = <0x21b8000 0x4000>;
				interrupts = <0x00 0x0e 0x04>;
				clocks = <0x01 0x8f>;
				fsl,weim-cs-gpr = <0x0e>;
				status = "disabled";
			};

			efuse@21bc000 {
				#address-cells = <0x01>;
				#size-cells = <0x01>;
				compatible = "fsl,imx6ul-ocotp\0syscon";
				reg = <0x21bc000 0x4000>;
				clocks = <0x01 0xa5>;

				calib@38 {
					reg = <0x38 0x04>;
					phandle = <0x1c>;
				};

				temp-grade@20 {
					reg = <0x20 0x04>;
					phandle = <0x1d>;
				};

				speed-grade@10 {
					reg = <0x10 0x04>;
					phandle = <0x04>;
				};
			};

			csi@21c4000 {
				compatible = "fsl,imx6ul-csi";
				reg = <0x21c4000 0x4000>;
				interrupts = <0x00 0x07 0x04>;
				clocks = <0x01 0x8a>;
				clock-names = "mclk";
				status = "okay";
				pinctrl-names = "default";
				pinctrl-0 = <0x30>;

				port {

					endpoint {
						remote-endpoint = <0x31>;
						bus-type = <0x05>;
						phandle = <0x2f>;
					};
				};
			};

			lcdif@21c8000 {
				compatible = "fsl,imx6ul-lcdif\0fsl,imx6sx-lcdif";
				reg = <0x21c8000 0x4000>;
				interrupts = <0x00 0x05 0x04>;
				clocks = <0x01 0xa2 0x01 0xa1 0x01 0x00>;
				clock-names = "pix\0axi\0disp_axi";
				status = "okay";
				assigned-clocks = <0x01 0x49>;
				assigned-clock-parents = <0x01 0x34>;
				pinctrl-names = "default";
				pinctrl-0 = <0x32 0x33>;

				port {

					endpoint {
						remote-endpoint = <0x34>;
						phandle = <0x3f>;
					};
				};
			};

			pxp@21cc000 {
				compatible = "fsl,imx6ul-pxp";
				reg = <0x21cc000 0x4000>;
				interrupts = <0x00 0x08 0x04>;
				clocks = <0x01 0xaf>;
				clock-names = "axi";
			};

			spi@21e0000 {
				#address-cells = <0x01>;
				#size-cells = <0x00>;
				compatible = "fsl,imx6ul-qspi";
				reg = <0x21e0000 0x4000 0x60000000 0x10000000>;
				reg-names = "QuadSPI\0QuadSPI-memory";
				interrupts = <0x00 0x6b 0x04>;
				clocks = <0x01 0xb0 0x01 0xb0>;
				clock-names = "qspi_en\0qspi";
				status = "okay";
				pinctrl-names = "default";
				pinctrl-0 = <0x35>;

				flash@0 {
					#address-cells = <0x01>;
					#size-cells = <0x01>;
					compatible = "micron,n25q256a\0jedec,spi-nor";
					spi-max-frequency = <0x1ba8140>;
					spi-rx-bus-width = <0x04>;
					spi-tx-bus-width = <0x01>;
					reg = <0x00>;
				};
			};

			watchdog@21e4000 {
				compatible = "fsl,imx6ul-wdt\0fsl,imx21-wdt";
				reg = <0x21e4000 0x4000>;
				interrupts = <0x00 0x0b 0x04>;
				clocks = <0x01 0xd2>;
				status = "disabled";
			};

			serial@21e8000 {
				compatible = "fsl,imx6ul-uart\0fsl,imx6q-uart";
				reg = <0x21e8000 0x4000>;
				interrupts = <0x00 0x1b 0x04>;
				clocks = <0x01 0xbf 0x01 0xc0>;
				clock-names = "ipg\0per";
				status = "okay";
				pinctrl-names = "default";
				pinctrl-0 = <0x36>;
				uart-has-rtscts;
			};

			serial@21ec000 {
				compatible = "fsl,imx6ul-uart\0fsl,imx6q-uart";
				reg = <0x21ec000 0x4000>;
				interrupts = <0x00 0x1c 0x04>;
				clocks = <0x01 0xc1 0x01 0xc2>;
				clock-names = "ipg\0per";
				status = "disabled";
			};

			serial@21f0000 {
				compatible = "fsl,imx6ul-uart\0fsl,imx6q-uart";
				reg = <0x21f0000 0x4000>;
				interrupts = <0x00 0x1d 0x04>;
				clocks = <0x01 0xc3 0x01 0xc4>;
				clock-names = "ipg\0per";
				status = "disabled";
			};

			serial@21f4000 {
				compatible = "fsl,imx6ul-uart\0fsl,imx6q-uart";
				reg = <0x21f4000 0x4000>;
				interrupts = <0x00 0x1e 0x04>;
				clocks = <0x01 0xc5 0x01 0xc6>;
				clock-names = "ipg\0per";
				status = "disabled";
			};

			i2c@21f8000 {
				#address-cells = <0x01>;
				#size-cells = <0x00>;
				compatible = "fsl,imx6ul-i2c\0fsl,imx21-i2c";
				reg = <0x21f8000 0x4000>;
				interrupts = <0x00 0x23 0x04>;
				clocks = <0x01 0x9f>;
				status = "disabled";
			};

			serial@21fc000 {
				compatible = "fsl,imx6ul-uart\0fsl,imx6q-uart";
				reg = <0x21fc000 0x4000>;
				interrupts = <0x00 0x11 0x04>;
				clocks = <0x01 0xc7 0x01 0xc8>;
				clock-names = "ipg\0per";
				status = "disabled";
			};
		};
	};

	memory@80000000 {
		device_type = "memory";
		reg = <0x80000000 0x20000000>;
	};

	backlight-display {
		compatible = "pwm-backlight";
		pwms = <0x37 0x00 0x4c4b40>;
		brightness-levels = <0x00 0x04 0x08 0x10 0x20 0x40 0x80 0xff>;
		default-brightness-level = <0x06>;
		status = "okay";
		phandle = <0x3e>;
	};

	regulator-sd1-vmmc {
		compatible = "regulator-fixed";
		regulator-name = "VSD_3V3";
		regulator-min-microvolt = <0x325aa0>;
		regulator-max-microvolt = <0x325aa0>;
		gpio = <0x0c 0x09 0x00>;
		enable-active-high;
		phandle = <0x29>;
	};

	regulator-peri-3v3 {
		compatible = "regulator-fixed";
		pinctrl-names = "default";
		pinctrl-0 = <0x38>;
		regulator-name = "VPERI_3V3";
		regulator-min-microvolt = <0x325aa0>;
		regulator-max-microvolt = <0x325aa0>;
		gpio = <0x39 0x02 0x01>;
		regulator-always-on;
		phandle = <0x15>;
	};

	regulator-can-3v3 {
		compatible = "regulator-fixed";
		regulator-name = "can-3v3";
		regulator-min-microvolt = <0x325aa0>;
		regulator-max-microvolt = <0x325aa0>;
		gpios = <0x2e 0x03 0x01>;
		phandle = <0x10>;
	};

	sound-wm8960 {
		compatible = "fsl,imx-audio-wm8960";
		model = "wm8960-audio";
		audio-cpu = <0x3a>;
		audio-codec = <0x3b>;
		audio-asrc = <0x3c>;
		hp-det-gpio = <0x39 0x04 0x00>;
		audio-routing = "Headphone Jack\0HP_L\0Headphone Jack\0HP_R\0Ext Spk\0SPK_LP\0Ext Spk\0SPK_LN\0Ext Spk\0SPK_RP\0Ext Spk\0SPK_RN\0LINPUT2\0Mic Jack\0LINPUT3\0Mic Jack\0RINPUT1\0AMIC\0RINPUT2\0AMIC\0Mic Jack\0MICB\0AMIC\0MICB";
	};

	spi-4 {
		compatible = "spi-gpio";
		pinctrl-names = "default";
		pinctrl-0 = <0x3d>;
		status = "okay";
		sck-gpios = <0x39 0x0b 0x00>;
		mosi-gpios = <0x39 0x0a 0x00>;
		cs-gpios = <0x39 0x07 0x01>;
		num-chipselects = <0x01>;
		#address-cells = <0x01>;
		#size-cells = <0x00>;

		gpio@0 {
			compatible = "fairchild,74hc595";
			gpio-controller;
			#gpio-cells = <0x02>;
			reg = <0x00>;
			registers-number = <0x01>;
			spi-max-frequency = <0x186a0>;
			enable-gpios = <0x39 0x08 0x01>;
			phandle = <0x2e>;

			eth0-phy-hog {
				gpio-hog;
				gpios = <0x01 0x00>;
				output-high;
				line-name = "eth0-phy";
			};

			eth1-phy-hog {
				gpio-hog;
				gpios = <0x02 0x00>;
				output-high;
				line-name = "eth1-phy";
			};
		};
	};

	panel {
		compatible = "innolux,at043tn24";
		backlight = <0x3e>;

		port {

			endpoint {
				remote-endpoint = <0x3f>;
				phandle = <0x34>;
			};
		};
	};
};
